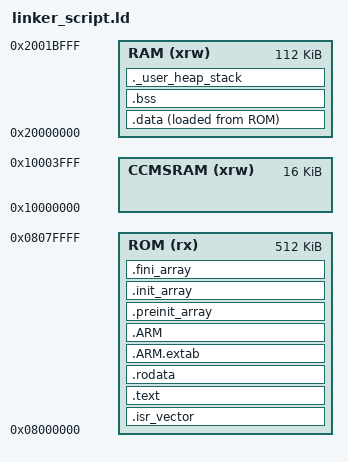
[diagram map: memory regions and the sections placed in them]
/*
 *****************************************************************************
 * linker_script.ld
 *
 * Linker script template for STM32 single core devices
 *
 * Investigate setting up project or device level definitions and then
 * including a common linker script that sets up everything needed for the c
 * runtime environment
 *
 * The common linker template can be used to build images that may have
 * the FLASH space divided up into multiple sections that support:
 *
 * BOOTSTRAP   (optional)
 * BOOTLOADER  (optional)
 * APPLICATION (required)
 * FILESYSTEM  (optional)
 * OTA         (optional)
 * CONFIG      (optional)
 *
 * Similary the RAM space can be set up with sections that support some
 * additional use cases such as:
 *
 * TRANSFER (optional space for transferring between bootloader and app)
 *
 * NOTE WELL: This file structure is being actively developed and is
 *            not yet complete. Try to keep the customization above and below
 *            the markers so that the common part of the file can be included
 *            as needed, and minimizes the projects and target specific
 *            linker script contents
 *****************************************************************************
 */

DEVICE_RAM_SIZE   = 8K;
DEVICE_FLASH_SIZE = 64K;

/* Add custom definitions ABOVE this line - everything below should
 * be included from a common file
 * -------------------------------------------------------------------------*/

/* Entry Point */
ENTRY(Reset_Handler)

/* Highest address of the user mode stack */
_estack = ORIGIN(RAM) + LENGTH(RAM);	/* end of "RAM" Ram type memory */

_Min_Heap_Size = 0x200;	/* required amount of heap  */
_Min_Stack_Size = 0x400;	/* required amount of stack */

/* Memories definition */
MEMORY
{
  CCMSRAM    (xrw)    : ORIGIN = 0x10000000,   LENGTH = 16K
  RAM    (xrw)    : ORIGIN = 0x20000000,   LENGTH = 112K
  ROM    (rx)    : ORIGIN = 0x08000000,   LENGTH = 512K
}

/* Sections */
SECTIONS
{
  /* The startup code into "ROM" Rom type memory */
  .isr_vector :
  {
    . = ALIGN(4);
    KEEP(*(.isr_vector)) /* Startup code */
    . = ALIGN(4);
  } >ROM

  /* The program code and other data into "ROM" Rom type memory */
  .text :
  {
    . = ALIGN(4);
    *(.text)           /* .text sections (code) */
    *(.text*)          /* .text* sections (code) */
    *(.glue_7)         /* glue arm to thumb code */
    *(.glue_7t)        /* glue thumb to arm code */
    *(.eh_frame)

    KEEP (*(.init))
    KEEP (*(.fini))

    . = ALIGN(4);
    _etext = .;        /* define a global symbols at end of code */
  } >ROM

  /* Constant data into "ROM" Rom type memory */
  .rodata :
  {
    . = ALIGN(4);
    *(.rodata)         /* .rodata sections (constants, strings, etc.) */
    *(.rodata*)        /* .rodata* sections (constants, strings, etc.) */
    . = ALIGN(4);
  } >ROM

  .ARM.extab (READONLY) : /* The READONLY keyword is only supported in GCC11 and later, remove it if using GCC10 or earlier. */
  {
    . = ALIGN(4);
    *(.ARM.extab* .gnu.linkonce.armextab.*)
    . = ALIGN(4);
  } >ROM
  
  .ARM (READONLY) : /* The READONLY keyword is only supported in GCC11 and later, remove it if using GCC10 or earlier. */
  {
    . = ALIGN(4);
    __exidx_start = .;
    *(.ARM.exidx*)
    __exidx_end = .;
    . = ALIGN(4);
  } >ROM

  .preinit_array (READONLY) : /* The READONLY keyword is only supported in GCC11 and later, remove it if using GCC10 or earlier. */
  {
    . = ALIGN(4);
    PROVIDE_HIDDEN (__preinit_array_start = .);
    KEEP (*(.preinit_array*))
    PROVIDE_HIDDEN (__preinit_array_end = .);
    . = ALIGN(4);
  } >ROM
  
  .init_array (READONLY) : /* The READONLY keyword is only supported in GCC11 and later, remove it if using GCC10 or earlier. */
  {
    . = ALIGN(4);
    PROVIDE_HIDDEN (__init_array_start = .);
    KEEP (*(SORT(.init_array.*)))
    KEEP (*(.init_array*))
    PROVIDE_HIDDEN (__init_array_end = .);
    . = ALIGN(4);
  } >ROM
  
  .fini_array (READONLY) : /* The READONLY keyword is only supported in GCC11 and later, remove it if using GCC10 or earlier. */
  {
    . = ALIGN(4);
    PROVIDE_HIDDEN (__fini_array_start = .);
    KEEP (*(SORT(.fini_array.*)))
    KEEP (*(.fini_array*))
    PROVIDE_HIDDEN (__fini_array_end = .);
    . = ALIGN(4);
  } >ROM

  /* Used by the startup to initialize data */
  _sidata = LOADADDR(.data);

  /* Initialized data sections into "RAM" Ram type memory */
  .data : 
  {
    . = ALIGN(4);
    _sdata = .;        /* create a global symbol at data start */
    *(.data)           /* .data sections */
    *(.data*)          /* .data* sections */

    . = ALIGN(4);
    _edata = .;        /* define a global symbol at data end */
    
  } >RAM AT> ROM

  /* Uninitialized data section into "RAM" Ram type memory */
  . = ALIGN(4);
  .bss :
  {
    /* This is used by the startup in order to initialize the .bss section */
    _sbss = .;         /* define a global symbol at bss start */
    __bss_start__ = _sbss;
    *(.bss)
    *(.bss*)
    *(COMMON)

    . = ALIGN(4);
    _ebss = .;         /* define a global symbol at bss end */
    __bss_end__ = _ebss;
  } >RAM

  /* User_heap_stack section, used to check that there is enough "RAM" Ram  type memory left */
  ._user_heap_stack :
  {
    . = ALIGN(8);
    PROVIDE ( end = . );
    PROVIDE ( _end = . );
    . = . + _Min_Heap_Size;
    . = . + _Min_Stack_Size;
    . = ALIGN(8);
  } >RAM

  /* Remove information from the compiler libraries */
  /DISCARD/ :
  {
    libc.a ( * )
    libm.a ( * )
    libgcc.a ( * )
  }

  .ARM.attributes 0 : { *(.ARM.attributes) }
}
